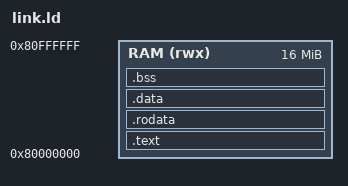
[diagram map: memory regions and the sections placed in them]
/* objects: norelocs/start.o norelocs/data.o norelocs/more.o */
OUTPUT_ARCH(riscv)
ENTRY(_start)

MEMORY { RAM (rwx) : ORIGIN = 0x80000000, LENGTH = 16M }

SECTIONS
{
    .text : { *(.text.start) *(.text*) } > RAM
    .rodata : { *(.rodata*) } > RAM
    .data : { *(.data*) } > RAM
    .bss : { *(.bss*) *(COMMON) } > RAM
    . = ALIGN(16);
    __heap_start = .;
    . += 4K;
    __stack_top = .;
}
